# GD32A72_A74x register map
File version: 1.0
CPU: CM7 r2p1, little endian, MPU, FPU, DSP, 4 interrupt priority bits
Registers are 32-bit, read-write, reset 0x0 unless marked. A register's access mark holds for its fields unless they carry their own. Offsets are from the block's base; [hi:lo] are bit positions; {n}, {i} and the like mark numbered series.

## DMA0 — Direct memory access controller
Base 0x49000000
Same registers: DMA1 0x49000400
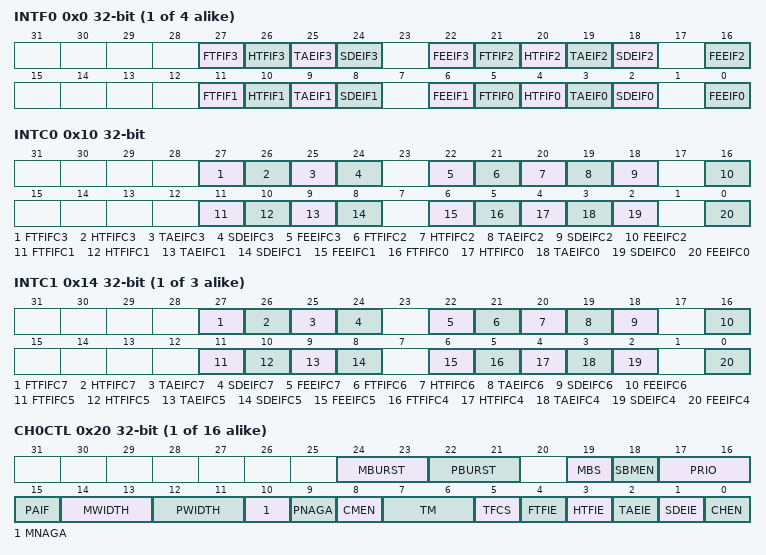
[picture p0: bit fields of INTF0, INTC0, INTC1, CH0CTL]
{0x0+4i} INTF{i} ro (i=0..3) — Interrupt flag register {i}
  [27] FTFIF{4i+3} — Full Transfer finish flag of channel {4i+3}
  [26] HTFIF{4i+3} — Half transfer finish flag of channel {4i+3}
  [25] TAEIF{4i+3} — Transfer access error flag of channel {4i+3}
  [24] SDEIF{4i+3} — Single data mode exception of channel {4i+3}
  [22] FEEIF{4i+3} — FIFO error and exception of channel {4i+3}
  [21] FTFIF{4i+2} — Full Transfer finish flag of channel {4i+2}
  [20] HTFIF{4i+2} — Half transfer finish flag of channel {4i+2}
  [19] TAEIF{4i+2} — Transfer access error flag of channel {4i+2}
  [18] SDEIF{4i+2} — Single data mode exception of channel {4i+2}
  [16] FEEIF{4i+2} — FIFO error and exception of channel {4i+2}
  [11] FTFIF{4i+1} — Full Transfer finish flag of channel {4i+1}
  [10] HTFIF{4i+1} — Half transfer finish flag of channel {4i+1}
  [9] TAEIF{4i+1} — Transfer access error flag of channel {4i+1}
  [8] SDEIF{4i+1} — Single data mode exception of channel {4i+1}
  [6] FEEIF{4i+1} — FIFO error and exception of channel {4i+1}
  [5] FTFIF{4i} — Full Transfer finish flag of channel {4i}
  [4] HTFIF{4i} — Half transfer finish flag of channel {4i}
  [3] TAEIF{4i} — Transfer access error flag of channel {4i}
  [2] SDEIF{4i} — Single data mode exception of channel {4i}
  [0] FEEIF{4i} — FIFO error and exception of channel {4i}
0x10 INTC0 wo — Interrupt flag clear register 0
  [27] FTFIFC3 — Clear bit for Full transfer finish flag of channel 3
  [26] HTFIFC3 — Clear bit for half transfer finish flag of channel 3
  [25] TAEIFC3 — Clear bit for ransfer access error flag of channel 3
  [24] SDEIFC3 — Clear bit for single data mode exception of channel 3
  [22] FEEIFC3 — Clear bit for FIFO error and exception of channel 3
  [21] FTFIFC2 — Clear bit for Full transfer finish flag of channel 2
  [20] HTFIFC2 — Clear bit for half transfer finish flag of channel 2
  [19] TAEIFC2 — Clear bit for ransfer access error flag of channel 2
  [18] SDEIFC2 — Clear bit for single data mode exception of channel 2
  [16] FEEIFC2 — Clear bit for FIFO error and exception of channel 2
  [11] FTFIFC1 — Clear bit for Full transfer finish flag of channel 1
  [10] HTFIFC1 — Clear bit for half transfer finish flag of channel 1
  [9] TAEIFC1 — Clear bit for ransfer access error flag of channel 1
  [8] SDEIFC1 — Clear bit for single data mode exception of channel 1
  [6] FEEIFC1 — Clear bit for FIFO error and exception of channel 1
  [5] FTFIFC0 — Clear bit for Full transfer finish flag of channel 0
  [4] HTFIFC0 — Clear bit for half transfer finish flag of channel 0
  [3] TAEIFC0 — Clear bit for ransfer access error flag of channel 0
  [2] SDEIFC0 — Clear bit for single data mode exception of channel 0
  [0] FEEIFC0 — Clear bit for FIFO error and exception of channel 0
{0x10+4i} INTC{i} wo (i=1..3) — Interrupt flag clear register {i}
  [27] FTFIFC{4i+3} — Clear bit for full transfer finish flag of channel {4i+3}
  [26] HTFIFC{4i+3} — Clear bit for half transfer finish flag of channel {4i+3}
  [25] TAEIFC{4i+3} — Clear bit for transfer access error flag of channel {4i+3}
  [24] SDEIFC{4i+3} — Clear bit for single data mode exception of channel {4i+3}
  [22] FEEIFC{4i+3} — Clear bit for FIFO error and exception of channel {4i+3}
  [21] FTFIFC{4i+2} — Clear bit for full transfer finish flag of channel {4i+2}
  [20] HTFIFC{4i+2} — Clear bit for half transfer finish flag of channel {4i+2}
  [19] TAEIFC{4i+2} — Clear bit for transfer access error flag of channel {4i+2}
  [18] SDEIFC{4i+2} — Clear bit for single data mode exception of channel {4i+2}
  [16] FEEIFC{4i+2} — Clear bit for FIFO error and exception of channel {4i+2}
  [11] FTFIFC{4i+1} — Clear bit for full transfer finish flag of channel {4i+1}
  [10] HTFIFC{4i+1} — Clear bit for half transfer finish flag of channel {4i+1}
  [9] TAEIFC{4i+1} — Clear bit for transfer access error flag of channel {4i+1}
  [8] SDEIFC{4i+1} — Clear bit for single data mode exception of channel {4i+1}
  [6] FEEIFC{4i+1} — Clear bit for FIFO error and exception of channel {4i+1}
  [5] FTFIFC{4i} — Clear bit for full transfer finish flag of channel {4i}
  [4] HTFIFC{4i} — Clear bit for half transfer finish flag of channel {4i}
  [3] TAEIFC{4i} — Clear bit for transfer access error flag of channel {4i}
  [2] SDEIFC{4i} — Clear bit for single data mode exception of channel {4i}
  [0] FEEIFC{4i} — Clear bit for FIFO error and exception of channel {4i}
{0x20+0x18*i} CH{i}CTL (i=0..15) — Channel {i} control register
  [24:23] MBURST — Transfer burst type of memory
  [22:21] PBURST — Transfer burst type of peripheral
  [19] MBS — Memory buffer select
  [18] SBMEN — Switch-buffer mode enable
  [17:16] PRIO — Priority level
  [15] PAIF — Peripheral address increment fixed
  [14:13] MWIDTH — Transfer width of memory
  [12:11] PWIDTH — Transfer width of peripheral
  [10] MNAGA — Next address generation algorithm of memory
  [9] PNAGA — Next address generation algorithm of peripheral
  [8] CMEN — Circular mode enable
  [7:6] TM — Transfer mode
  [5] TFCS — Transfer flow controller select
  [4] FTFIE — Enable bit for full transfer finish interrupt
  [3] HTFIE — Enable bit for half transfer finish interrupt
  [2] TAEIE — Enable bit for tranfer access error interrupt
  [1] SDEIE — Enable bit for single data mode exception interrupt
  [0] CHEN — Channel enable
{0x24+0x18*i} CH{i}CNT (i=0..15) — Channel {i} counter register
  [15:0] CNT — Transfer counter
{0x28+0x18*i} CH{i}PADDR (i=0..15) — Channel {i} peripheral base address register
  [31:0] PADDR — Peripheral base address
{0x2C+0x18*i} CH{i}M0ADDR (i=0..15) — Channel {i} memory 0 base address register
  [31:0] M0ADDR — Memory 0 base address
{0x30+0x18*i} CH{i}M1ADDR (i=0..15) — Channel {i} memory 1 base address register
  [31:0] M1ADDR — Memory 1 base address
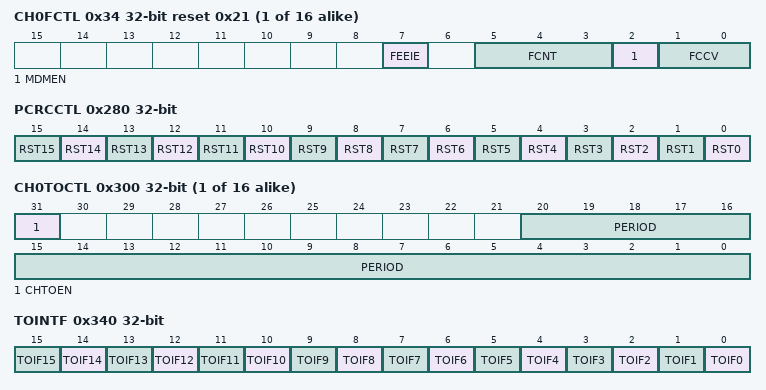
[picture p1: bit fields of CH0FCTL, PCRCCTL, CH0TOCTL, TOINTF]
{0x34+0x18*i} CH{i}FCTL access per field reset 0x21 (i=0..15) — Channel {i} FIFO control register
  [7] FEEIE rw — Enable bit for FIFO error and exception interrupt
  [5:3] FCNT ro — FIFO counter
  [2] MDMEN rw — Multi-data mode enable
  [1:0] FCCV rw — FIFO counter critical value
{0x200+4i} CH{i}PCRCDATA ro reset 0xFFFFFFFF (i=0..15) — Channel {i} peripheral CRC data register
  [31:0] CRC_PDATA — Peripheral port CRC data
0x240 CRCIDATA reset 0xFFFFFFFF — CRC initialization data register
  [31:0] CRC_IDATA — CRC initialization data value
0x280 PCRCCTL wo — Peripheral port CRC control register
  [n] RST{n} (n=0..15) — Reset bit
{0x300+4i} CH{i}TOCTL (i=0..15) — Channel {i} transfer timeout monitor control register
  [31] CHTOEN — Channel transfer timeout monitor enable
  [20:0] PERIOD — The timeout threshold value
0x340 TOINTF — Timeout interrupt flag register
  [n] TOIF{n} (n=0..15) — Transfer timeout flag of channel {n}
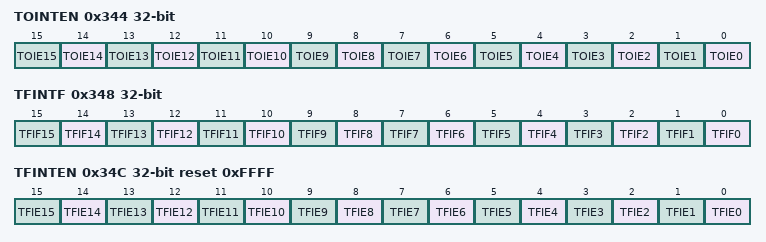
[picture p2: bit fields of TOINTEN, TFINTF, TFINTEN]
0x344 TOINTEN — Timeout interrupt register
  [n] TOIE{n} (n=0..15) — Transfer timeout interrupt of channel {n} enable
0x348 TFINTF — TMR fault interrupt flag register
  [n] TFIF{n} (n=0..15) — TMR fault flag of channel {n} control register
0x34C TFINTEN reset 0xFFFF — TMR fault interrupt enable register
  [n] TFIE{n} (n=0..15) — TMR fault interrupt enable of channel {n} control register
{0x350+4i} CH{i}PCADDR ro (i=0..15) — Channel {i} peripheral port current address register
  [31:0] PADDR — Peripheral port address pointing to the peripheral port data
{0x390+4i} CH{i}MCADDR ro (i=0..15) — Channel {i} memory port current address register
  [31:0] MADDR — Memory port address pointing to the memory port data
